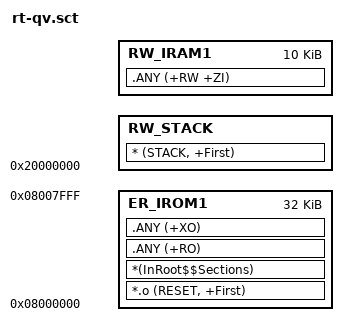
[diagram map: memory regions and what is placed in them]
; *************************************************************
; *** Scatter-Loading Description File generated by uVision ***
;
; Adapted by Quantum Leaps:
; moved STACK as the first section in RW_STACK
; *************************************************************

LR_IROM1 0x08000000 0x00008000  {    ; load region size_region
  ER_IROM1 0x08000000 0x00008000  {  ; load address = execution address
   *.o (RESET, +First)
   *(InRoot$$Sections)
   .ANY (+RO)
   .ANY (+XO)
  }

  RW_STACK 0x20000000 {
   * (STACK, +First)
  }
  RW_IRAM1 +0 (0x00003000 - 2048) {
   .ANY (+RW +ZI)
  }
}

